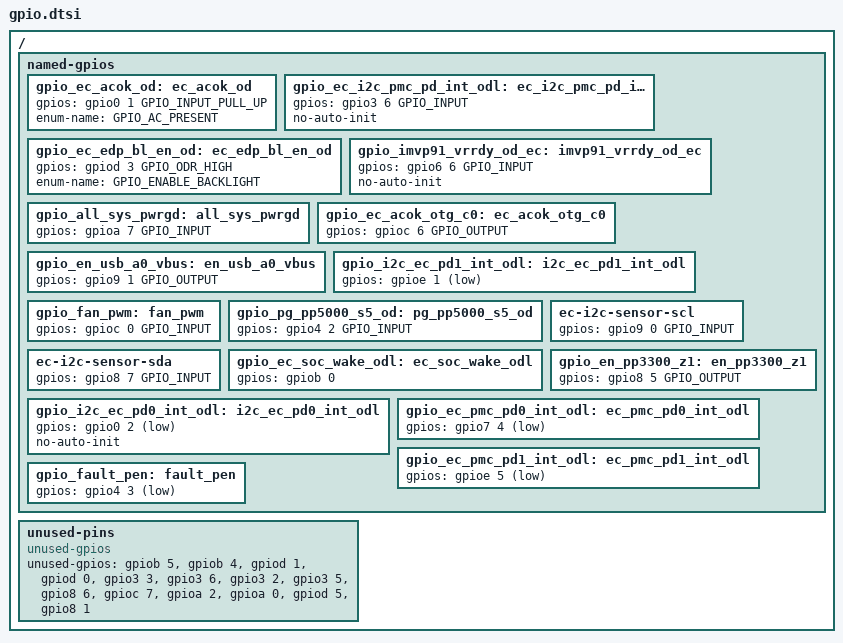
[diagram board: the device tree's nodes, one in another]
/* Copyright 2025 The ChromiumOS Authors
 * Use of this source code is governed by a BSD-style license that can be
 * found in the LICENSE file.
 */

 / {

	named-gpios {
		/delete-node/ acok_od;
		/delete-node/ amp_mute_l;
		/delete-node/ charger_vap_otg_en;
		/delete-node/ ec_pmc_pd_int_odl;
		/delete-node/ gsc_ec_pwr_btn_odl;
		/delete-node/ ec_tris_l;
		/delete-node/ en_kb_bl;
		/delete-node/ en_pp5000_pen_x;
		/delete-node/ en_z1_rails;
		/delete-node/ imvp91_vrrdy_r_od;
		/delete-node/ pdc_rst;
		/delete-node/ vccin_aux_r_vid0;
		/delete-node/ vccin_aux_r_vid1;
		/delete-node/ all_sys_pwrgd;
		/delete-node/ pg_pp5000_z1_od;
		/delete-node/ tablet_mode_l;
		/delete-node/ imu_int_l;
		/delete-node/ acc_int_l;
		/delete-node/ i2c_ec_pd_int_odl;
		/delete-node/ voldn_btn_odl;
		/delete-node/ en_kb_bl;
		/delete-node/ volup_btn_odl;
		/delete-node/ voldn_btn_odl;
		/delete-node/ ccd_mode_odl;
		

		gpio_ec_acok_od: ec_acok_od {
			gpios = <&gpio0 1 GPIO_INPUT_PULL_UP>;
			enum-name = "GPIO_AC_PRESENT";
		};
		gpio_ec_i2c_pmc_pd_int_odl: ec_i2c_pmc_pd_int_odl {
			gpios = <&gpio3 6 GPIO_INPUT>;
		};
		gpio_ec_edp_bl_en_od: ec_edp_bl_en_od {
			gpios = <&gpiod 3 GPIO_ODR_HIGH>;
			enum-name = "GPIO_ENABLE_BACKLIGHT";
		};
		gpio_imvp91_vrrdy_od_ec: imvp91_vrrdy_od_ec {
			gpios = <&gpio6 6 GPIO_INPUT>;
			no-auto-init;
		};
		gpio_all_sys_pwrgd: all_sys_pwrgd {
			gpios = <&gpioa 7 GPIO_INPUT>;
		};
		gpio_ec_acok_otg_c0: ec_acok_otg_c0 {
			gpios = <&gpioc 6 GPIO_OUTPUT>;
		};
		gpio_en_usb_a0_vbus: en_usb_a0_vbus {
			gpios = <&gpio9 1 GPIO_OUTPUT>;
		};
		gpio_i2c_ec_pd1_int_odl: i2c_ec_pd1_int_odl {
			gpios = <&gpioe 1 (GPIO_INPUT | GPIO_ACTIVE_LOW)>;
		};
		gpio_fan_pwm: fan_pwm {
			gpios = <&gpioc 0 GPIO_INPUT>;
		};
		gpio_pg_pp5000_s5_od: pg_pp5000_s5_od {
			gpios = <&gpio4 2 GPIO_INPUT>;
		};
		ec-i2c-sensor-scl {
			gpios = <&gpio9 0 GPIO_INPUT>;
		};
		ec-i2c-sensor-sda {
			gpios = <&gpio8 7 GPIO_INPUT>;
		};
		gpio_ec_soc_wake_odl: ec_soc_wake_odl {
			gpios = <&gpiob 0 (GPIO_OUTPUT | GPIO_OPEN_DRAIN | GPIO_OUTPUT_INIT_LOW)>;
		};
		gpio_en_pp3300_z1: en_pp3300_z1 {
			gpios = <&gpio8 5 GPIO_OUTPUT>;
		};
		gpio_i2c_ec_pd0_int_odl: i2c_ec_pd0_int_odl {
			gpios = <&gpio0 2 (GPIO_INPUT | GPIO_ACTIVE_LOW)>;
		};
		gpio_ec_pmc_pd0_int_odl: ec_pmc_pd0_int_odl {
			gpios = <&gpio7 4 (GPIO_OUTPUT | GPIO_OPEN_DRAIN | GPIO_ACTIVE_LOW)>;
		};
		gpio_ec_pmc_pd1_int_odl: ec_pmc_pd1_int_odl {
			gpios = <&gpioe 5 (GPIO_OUTPUT | GPIO_OPEN_DRAIN | GPIO_ACTIVE_LOW)>;
		};
		gpio_fault_pen: fault_pen {
			gpios = <&gpio4 3 (GPIO_INPUT | GPIO_ACTIVE_LOW)>;
		};
	};

	unused-pins {
		compatible = "unused-gpios";
		unused-gpios =
			<&gpiob 5 0>,
			<&gpiob 4 0>,
			<&gpiod 1 0>,
			<&gpiod 0 0>,
			<&gpio3 3 0>,
			<&gpio3 6 0>,
			<&gpio3 2 0>,
			<&gpio3 5 0>,
			<&gpio8 6 0>,
			<&gpioc 7 0>,
			<&gpioa 2 0>,
			<&gpioa 0 0>,
			<&gpiod 5 0>,
			<&gpio8 1 0>;
	};
};

/* These GPIOS are initialized by the PDC driver */
&gpio_i2c_ec_pd0_int_odl {
	no-auto-init;
};
&gpio_ec_i2c_pmc_pd_int_odl {
	no-auto-init;
};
